AUTOSAR XML (schema 4-0-3)
package /SystemDescription
  client server interface Interface
    operation Operation
      arg angle: type=ImplDataType, direction=IN
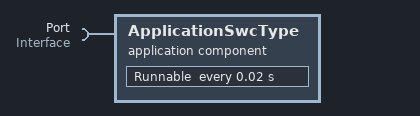
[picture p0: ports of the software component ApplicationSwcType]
  application sw component type ApplicationSwcType
    require port Port: required-interface=Interface
    behavior InternalBehaviorName: handle-termination-and-restart=NO-SUPPORT
      timing event TimingEventName: start-on-event=Runnable, period=0.02
      runnable Runnable
        sync call ServerCallPoint_Runnable_Port_Operation: operation=Port.Operation, timeout=0.0
